# CC1314R10 register map
File version: 1.0
CPU: CM33 1.0, other endian, MPU, FPU, 3 interrupt priority bits
Registers are 32-bit, read-write, reset 0x0 unless marked. A register's access mark holds for its fields unless they carry their own. Offsets are from the block's base; [hi:lo] are bit positions; {n}, {i} and the like mark numbered series; <NAME> marks a mode.

## AUX_MAC — The AUX Multiply-Accumulate (AUX_MAC) peripheral enables AUX_SCE with power-efficient and flexible mathematical operations: - 2's complement signed and unsigned sequential multiplication (MUL) with optional accumulation of the result (MAC). - 16 or 32-bit 2's complement signed and unsigned addition of configurable term and accumulator (ADD). - Results of ADD, MUL and MAC operations are always stored in the accumulator (ACC). Software can easily: - Access arbitrary 16-bit slice of the 40-bit accumulator. - Find the number of leading zero or sign bits. - Perform shift operations on the accumulator. AUX_SCE must set AUX_SYSIF:PEROPRATE.MAC_OP_RATE to SCE_RATE to access and use AUX_MAC. System CPU must set AUX_SYSIF:PEROPRATE.MAC_OP_RATE to BUS_RATE to access and use AUX_MAC. This guarantees constant execution times for ADD, MUL, and MAC operations. The ADD operation requires a single peripheral clock cycle to finish. MUL and MAC operations require four peripheral clock periods to finish. An unfinished ADD, MUL, or MAC operation stalls register access to this peripheral. AUX_SCE becomes clock gated if it encounters a bus stall. Software can use this to reduce power consumption during back to back accesses. Only full word access is supported by the peripheral. An attempt to write a single byte will have no effect.
Base 0x400C2000
0x00 OP0S — Signed Operand 0
  [15:0] OP0_VALUE wo — [15:0] Signed operand 0. Operand for multiply, multiply-and-accumulate, or 32-bit add operations.
0x04 OP0U — Unsigned Operand 0
  [15:0] OP0_VALUE wo — [15:0] Unsigned operand 0. Operand for multiply, multiply-and-accumulate, or 32-bit add operations.
0x08 OP1SMUL — Signed Operand 1 and Multiply
  [15:0] OP1_VALUE wo — [15:0] Signed operand 1 and multiplication trigger. Write OP1_VALUE to set signed operand 1 and trigger the following operation: When operand 0 was written to OP0S.OP0_VALUE: ACC = OP1_VALUE * OP0S.OP0_VALUE. When operand 0 was written to OP0U.OP0_VALUE: ACC = OP1_VALUE * OP0U.OP0_VALUE.
0x0C OP1UMUL — Unsigned Operand 1 and Multiply
  [15:0] OP1_VALUE wo — [15:0] Unsigned operand 1 and multiplication trigger. Write OP1_VALUE to set unsigned operand 1 and trigger the following operation: When operand 0 was written to OP0S.OP0_VALUE: ACC = OP1_VALUE * OP0S.OP0_VALUE. When operand 0 was written to OP0U.OP0_VALUE: ACC = OP1_VALUE * OP0U.OP0_VALUE.
0x10 OP1SMAC — Signed Operand 1 and Multiply-Accumulate
  [15:0] OP1_VALUE wo — [15:0] Signed operand 1 and multiply-accumulation trigger. Write OP1_VALUE to set signed operand 1 and trigger the following operation: When operand 0 was written to OP0S.OP0_VALUE: ACC = ACC + ( OP1_VALUE * OP0S.OP0_VALUE ). When operand 0 was written to OP0U.OP0_VALUE: ACC = ACC + ( OP1_VALUE * OP0U.OP0_VALUE ).
0x14 OP1UMAC — Unsigned Operand 1 and Multiply-Accumulate
  [15:0] OP1_VALUE wo — [15:0] Unsigned operand 1 and multiply-accumulation trigger. Write OP1_VALUE to set unsigned operand 1 and trigger the following operation: When operand 0 was written to OP0S.OP0_VALUE: ACC = ACC + ( OP1_VALUE * OP0S.OP0_VALUE ). When operand 0 was written to OP0U.OP0_VALUE: ACC = ACC + ( OP1_VALUE * OP0U.OP0_VALUE ).
0x18 OP1SADD16 — Signed Operand 1 and 16-bit Addition
  [15:0] OP1_VALUE wo — [15:0] Signed operand 1 and 16-bit addition trigger. Write OP1_VALUE to set signed operand 1 and trigger the following operation: ACC = ACC + OP1_VALUE.
0x1C OP1UADD16 — Unsigned Operand 1 and 16-bit Addition
  [15:0] OP1_VALUE wo — [15:0] Unsigned operand 1 and 16-bit addition trigger. Write OP1_VALUE to set unsigned operand 1 and trigger the following operation: ACC = ACC + OP1_VALUE.
0x20 OP1SADD32 — Signed Operand 1 and 32-bit Addition
  [15:0] OP1_VALUE wo — [15:0] Upper half of signed 32-bit operand and addition trigger. Write OP1_VALUE to set upper half of signed 32-bit operand and trigger the following operation: When lower half of 32-bit operand was written to OP0S.OP0_VALUE: ACC = ACC + (( OP1_VALUE << 16) | OP0S.OP0_VALUE ). When lower half of 32-bit operand was written to OP0U.OP0_VALUE: ACC = ACC + (( OP1_VALUE << 16) | OP0U.OP0_VALUE ).
0x24 OP1UADD32 — Unsigned Operand 1 and 32-bit Addition
  [15:0] OP1_VALUE wo — [15:0] Upper half of unsigned 32-bit operand and addition trigger. Write OP1_VALUE to set upper half of unsigned 32-bit operand and trigger the following operation: When lower half of 32-bit operand was written to OP0S.OP0_VALUE: ACC = ACC + (( OP1_VALUE << 16) | OP0S.OP0_VALUE ). When lower half of 32-bit operand was written to OP0U.OP0_VALUE: ACC = ACC + (( OP1_VALUE << 16) | OP0U.OP0_VALUE ).
0x28 CLZ reset 0x28 — Count Leading Zero
  [5:0] VALUE ro — [5:0] Number of leading zero bits in the accumulator: 0x00: 0 leading zeros. 0x01: 1 leading zero. ... 0x28: 40 leading zeros (accumulator value is 0).
0x2C CLS reset 0x28 — Count Leading Sign
  [5:0] VALUE ro — [5:0] Number of leading sign bits in the accumulator. When MSB of accumulator is 0, VALUE is number of leading zeros, MSB included. When MSB of accumulator is 1, VALUE is number of leading ones, MSB included. VALUE range is 1 thru 40.
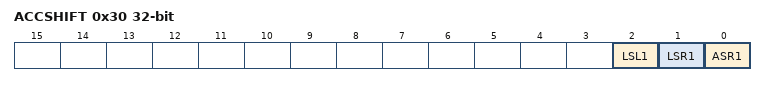
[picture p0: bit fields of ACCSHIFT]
0x30 ACCSHIFT — Accumulator Shift Only one shift operation can be triggered per register write.
  [2] LSL1 wo — [2:2] Logic shift left by 1 bit. Write 1 to shift the accumulator one bit to the left, 0 inserted at bit 0.
  [1] LSR1 wo — [1:1] Logic shift right by 1 bit. Write 1 to shift the accumulator one bit to the right, 0 inserted at bit 39.
  [0] ASR1 wo — [0:0] Arithmetic shift right by 1 bit. Write 1 to shift the accumulator one bit to the right, previous sign bit inserted at bit 39.
0x34 ACCRESET — Accumulator Reset
  [15:0] TRG wo — [15:0] Write any value to this register to trigger a reset of all bits in the accumulator.
0x38 ACC15_0 — Accumulator Bits 15:0
  [15:0] VALUE — [15:0] Value of the accumulator, bits 15:0. Write VALUE to initialize bits 15:0 of accumulator.
{0x38+4i} ACC{i+15}_{i} (i=1..15) — Accumulator Bits {i+15}:{i}
  [15:0] VALUE ro — [15:0] Value of the accumulator, bits {i+15}:{i}.
0x78 ACC31_16 — Accumulator Bits 31:16
  [15:0] VALUE — [15:0] Value of the accumulator, bits 31:16. Write VALUE to initialize bits 31:16 of accumulator.
{0x38+4i} ACC{i+15}_{i} (i=17..24) — Accumulator Bits {i+15}:{i}
  [15:0] VALUE ro — [15:0] Value of the accumulator, bits {i+15}:{i}.
0x9C ACC39_32 — Accumulator Bits 39:32
  [7:0] VALUE — [7:0] Value of the accumulator, bits 39:32. Write VALUE to initialize bits 39:32 of accumulator.
